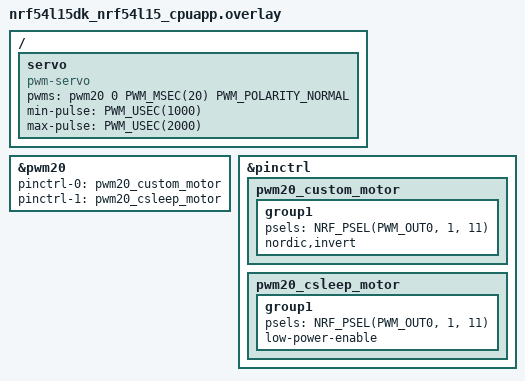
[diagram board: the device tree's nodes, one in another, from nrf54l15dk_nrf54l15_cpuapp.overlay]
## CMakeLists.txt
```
# SPDX-License-Identifier: Apache-2.0

cmake_minimum_required(VERSION 3.20.0)

find_package(Zephyr REQUIRED HINTS $ENV{ZEPHYR_BASE})
project(remote_controller)

target_sources(app PRIVATE src/main.c)
# Custom files and folders

target_sources(app PRIVATE
    src/custom_files/motor_control.c
)

zephyr_library_include_directories(src/custom_files)
```

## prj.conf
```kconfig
# Step 2.1 
# Configure logger
CONFIG_LOG=y
CONFIG_USE_SEGGER_RTT=n
CONFIG_LOG_BACKEND_UART=y
CONFIG_LOG_DEFAULT_LEVEL=3

#Step 2.7
#Configure DK Buttons and LEDS:
CONFIG_DK_LIBRARY=y

CONFIG_PWM=y
```

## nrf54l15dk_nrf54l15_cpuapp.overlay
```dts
// To get started, press Ctrl+Space to bring up the completion menu and view the available nodes.

// You can also use the buttons in the sidebar to perform actions on nodes.
// Actions currently available include:

// * Enabling / disabling the node
// * Adding the bus to a bus
// * Removing the node
// * Connecting ADC channels

// For more help, browse the DeviceTree documentation at https://docs.zephyrproject.org/latest/guides/dts/index.html
// You can also visit the nRF DeviceTree extension documentation at https://docs.nordicsemi.com/bundle/nrf-connect-vscode/page/guides/ncs_configure_app.html#devicetree-support-in-the-extension

/ {
    servo: servo {
        compatible = "pwm-servo";
        pwms = <&pwm20 0 PWM_MSEC(20) PWM_POLARITY_NORMAL>;
        min-pulse = <PWM_USEC(1000)>;
        max-pulse = <PWM_USEC(2000)>;
    };
};

/* STEP 5.3 - Configure which pins pwm1 should use */
&pwm20 {
    status = "okay";
    pinctrl-0 = <&pwm20_custom_motor>;
    pinctrl-1 = <&pwm20_csleep_motor>;
    pinctrl-names = "default", "sleep";
};

&pinctrl {
    pwm20_custom_motor: pwm20_custom_motor {
        group1 {
            psels = <NRF_PSEL(PWM_OUT0, 1, 11)>; /* Original is 1.10 */
            nordic,invert;
        };
    };

    pwm20_csleep_motor: pwm20_csleep_motor {
        group1 {
            psels = <NRF_PSEL(PWM_OUT0, 1, 11)>; 
            low-power-enable;
        };
    };
};
```

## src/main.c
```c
/*
 * Copyright (c) 2012-2014 Wind River Systems, Inc.
 *
 * SPDX-License-Identifier: Apache-2.0
 */


#include <zephyr/logging/log.h>
#include <dk_buttons_and_leds.h>
#include <zephyr/kernel.h>
#include "motor_control.h"

#define LOG_MODULE_NAME app
LOG_MODULE_REGISTER(LOG_MODULE_NAME);


#define RUN_STATUS_LED DK_LED1
#define RUN_LED_BLINK_INTERVAL 1000

#define SERVO_MOTOR    DT_NODELABEL(servo)
#define PWM_SERVO_MIN_DUTY_CYCLE  DT_PROP(SERVO_MOTOR, min_pulse)
#define PWM_SERVO_MAX_DUTY_CYCLE  DT_PROP(SERVO_MOTOR, max_pulse)


void button_handler(uint32_t button_state, uint32_t has_changed)
{
	int button_pressed = 0;
    int err = 0;
	if (has_changed & button_state)
	{
		switch (has_changed)
		{
			case DK_BTN1_MSK:
				button_pressed = 1;
				err = set_motor_angle(PWM_SERVO_MIN_DUTY_CYCLE);
				break;
			case DK_BTN2_MSK:
				button_pressed = 2;
				err = set_motor_angle(PWM_SERVO_MAX_DUTY_CYCLE);
				break;
			case DK_BTN3_MSK:
				button_pressed = 3;
				break;
			case DK_BTN4_MSK:
				button_pressed = 4;
				break;
			default:
				break;
		}
        if (err) {
            LOG_ERR("Error: couldn't set duty cycle, err %d", err);
        }
	}
}
static void configure_dk_buttons_and_leds(void){
	int err;

	err = dk_leds_init();
	if(err){
		LOG_ERR("Couldn't init LEDS (err %d)", err);
	}
	
    err = dk_buttons_init(button_handler);
    if (err) {
        LOG_ERR("Couldn't init buttons (err %d)", err);
    }
}

int main(void)
{

	int err = 0;
	bool blink_status = false;

	printf("Hello World! %s\n", CONFIG_BOARD);

	configure_dk_buttons_and_leds();

	err = motor_init();
    if (err) {
        LOG_ERR("motor_init() failed. (err %d)", err);
    }
	
	for (;;){
		dk_set_led(RUN_STATUS_LED, (blink_status));
		blink_status = !blink_status;
		k_sleep(K_MSEC(RUN_LED_BLINK_INTERVAL));


	}

	return 0;
}
```
